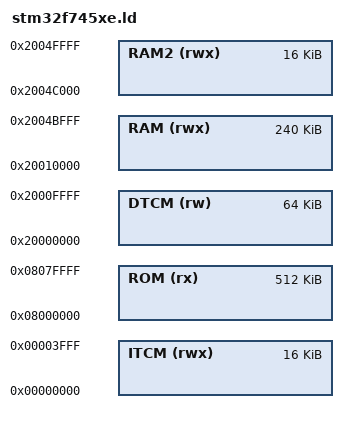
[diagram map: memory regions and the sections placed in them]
ENTRY(Reset_Handler)
MEMORY
{
    ROM   (rx): ORIGIN = 0x08000000, LENGTH = 512K
    ITCM (rwx): ORIGIN = 0x00000000, LENGTH = 16K
    DTCM (rw):  ORIGIN = 0x20000000, LENGTH = 64K
    RAM  (rwx): ORIGIN = 0x20010000, LENGTH = 240K
    RAM2 (rwx): ORIGIN = 0x2004C000, LENGTH = 16K
}

INCLUDE sections.ld
